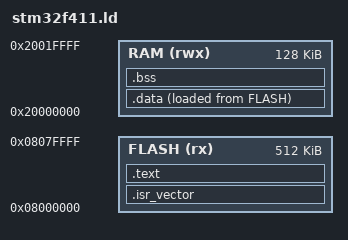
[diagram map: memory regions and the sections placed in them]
/* STM32F411CEU6 Linker Script */
ENTRY(Reset_Handler)

MEMORY
{
    FLASH (rx) : ORIGIN = 0x08000000, LENGTH = 512K
    RAM  (rwx) : ORIGIN = 0x20000000, LENGTH = 128K
}

SECTIONS
{
    .isr_vector :
    {
        . = ALIGN(4);
        KEEP(*(.isr_vector))
        . = ALIGN(4);
    } > FLASH

    .text :
    {
        . = ALIGN(4);
        *(.text)
        *(.text*)
        *(.rodata)
        *(.rodata*)
        . = ALIGN(4);
        _etext = .;
    } > FLASH

    _la_data = LOADADDR(.data);

    .data :
    {
        _sdata = .;
        *(.data)
        *(.data*)
        . = ALIGN(4);
        _edata = .;
    } > RAM AT > FLASH

    .bss :
    {
        _sbss = .;
        __bss_start__ = _sbss;
        *(.bss)
        *(.bss*)
        *(COMMON)
        . = ALIGN(4);
        _ebss = .;
        __bss_end__ = _ebss;
    } > RAM

    . = ALIGN(4);
    end = .;
    __end__ = .;

    /* Stack starts at end of RAM */
    _estack = ORIGIN(RAM) + LENGTH(RAM);
}
